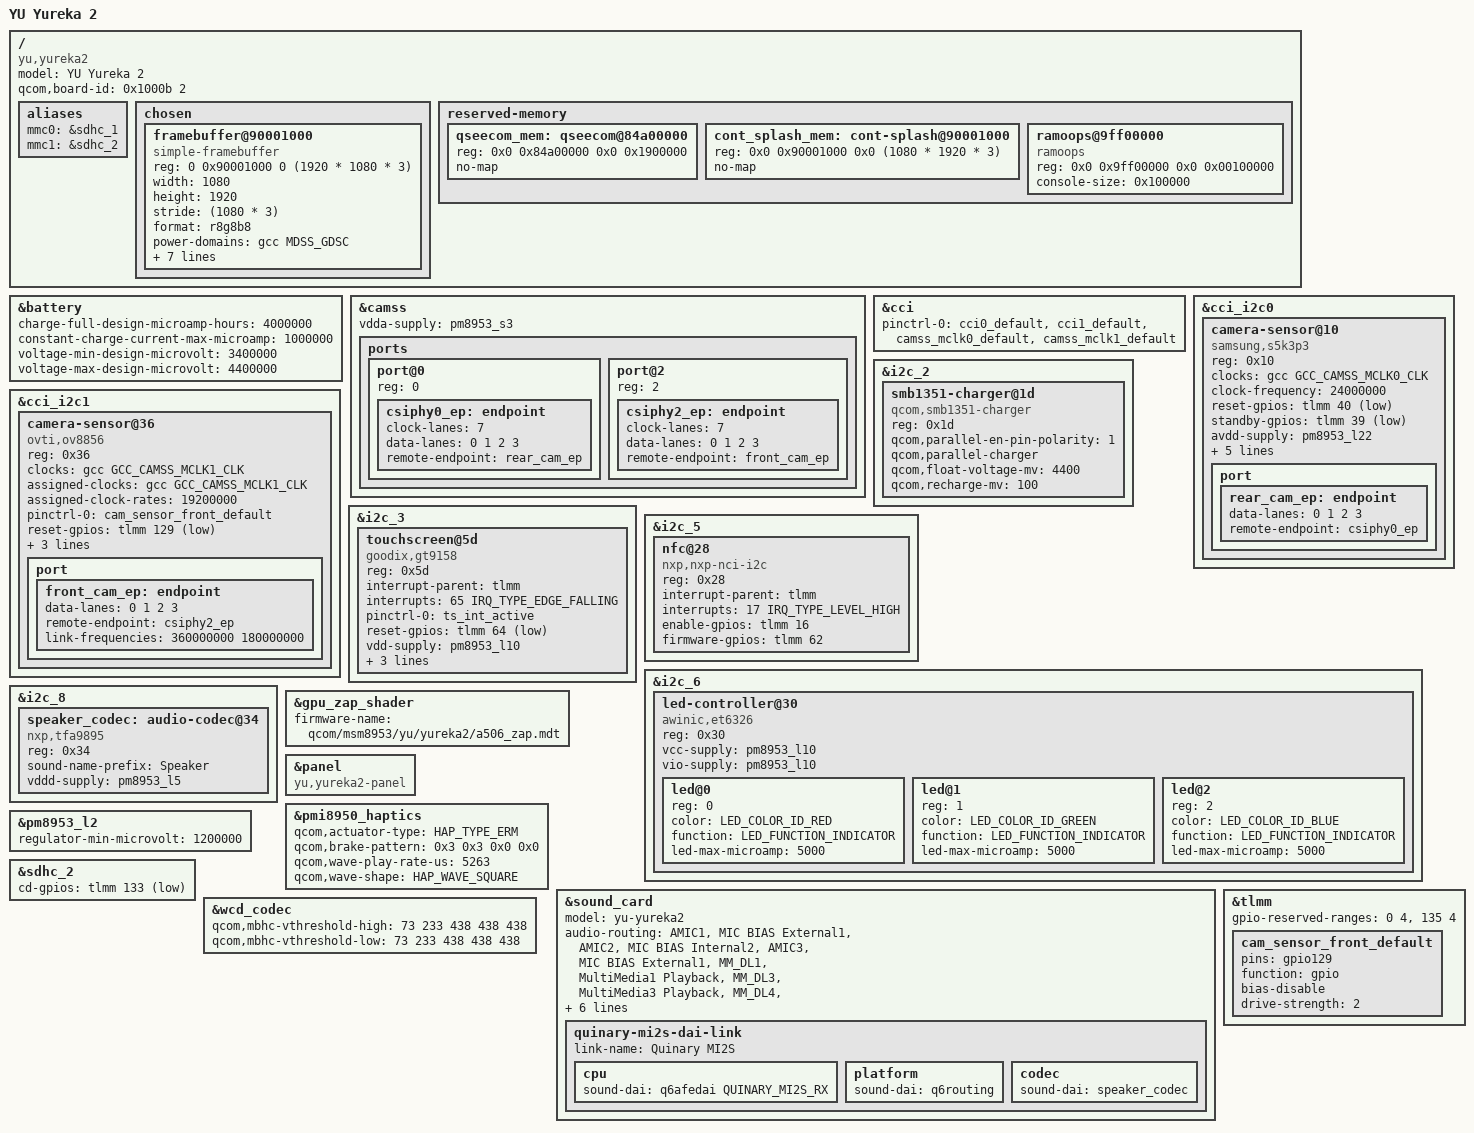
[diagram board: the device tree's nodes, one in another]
// SPDX-License-Identifier: BSD-3-Clause
/dts-v1/;

#include "msm8953-yu-common.dtsi"

/delete-node/ &cont_splash_mem;
/delete-node/ &qseecom_mem;

/ {
	model = "YU Yureka 2";
	compatible = "yu,yureka2", "qcom,msm8953";
	qcom,board-id = <0x1000b 2>;

	aliases {
		mmc0 = &sdhc_1;
		mmc1 = &sdhc_2;
	};

	chosen {
		#address-cells = <2>;
		#size-cells = <2>;
		ranges;

		framebuffer@90001000 {
			compatible = "simple-framebuffer";
			reg = <0 0x90001000 0 (1920 * 1080 * 3)>;

			width = <1080>;
			height = <1920>;
			stride = <(1080 * 3)>;
			format = "r8g8b8";

			power-domains = <&gcc MDSS_GDSC>;

			clocks = <&gcc GCC_MDSS_AHB_CLK>,
				 <&gcc GCC_MDSS_AXI_CLK>,
				 <&gcc GCC_MDSS_VSYNC_CLK>,
				 <&gcc GCC_MDSS_MDP_CLK>,
				 <&gcc GCC_MDSS_BYTE0_CLK>,
				 <&gcc GCC_MDSS_PCLK0_CLK>,
				 <&gcc GCC_MDSS_ESC0_CLK>;
		};
	};

	reserved-memory {
		qseecom_mem: qseecom@84a00000 {
			reg = <0x0 0x84a00000 0x0 0x1900000>;
			no-map;
		};

		cont_splash_mem: cont-splash@90001000 {
			reg = <0x0 0x90001000 0x0 (1080 * 1920 * 3)>;
			no-map;
		};

		ramoops@9ff00000 {
			compatible = "ramoops";
			reg = <0x0 0x9ff00000 0x0 0x00100000>;
			console-size = <0x100000>;
		};
	};
};

&battery {
	charge-full-design-microamp-hours = <4000000>;
	constant-charge-current-max-microamp = <1000000>;
	voltage-min-design-microvolt = <3400000>;
	voltage-max-design-microvolt = <4400000>;
};

&camss {
	status = "okay";
	vdda-supply = <&pm8953_s3>;

	ports {
		port@0 {
			reg = <0>;
			csiphy0_ep: endpoint {
				clock-lanes = <7>;
				data-lanes = <0 1 2 3>;
				remote-endpoint = <&rear_cam_ep>;
			};
		};

		port@2 {
			reg = <2>;
			csiphy2_ep: endpoint {
				clock-lanes = <7>;
				data-lanes = <0 1 2 3>;
				remote-endpoint = <&front_cam_ep>;
			};
		};
	};
};

&cci {
	pinctrl-names = "default";
	pinctrl-0 = <&cci0_default>,
		    <&cci1_default>,
		    <&camss_mclk0_default>,
		    <&camss_mclk1_default>;

	status = "okay";
};

&cci_i2c0 {
	camera-sensor@10 {
		compatible = "samsung,s5k3p3";
		reg = <0x10>;

		clocks = <&gcc GCC_CAMSS_MCLK0_CLK>;
		clock-frequency = <24000000>;

		reset-gpios = <&tlmm 40 GPIO_ACTIVE_LOW>;
		standby-gpios = <&tlmm 39 GPIO_ACTIVE_LOW>;

		avdd-supply = <&pm8953_l22>;
		dvdd-supply = <&pm8953_l2>;
		vio-supply = <&pm8953_l6>;
		aux-supply = <&pm8953_l17>;

		rotation = <270>;
		orientation = <1>;

		status = "okay";

		port {
			rear_cam_ep: endpoint {
				data-lanes = <0 1 2 3>;
				remote-endpoint = <&csiphy0_ep>;
			};
		};
	};
};

&cci_i2c1 {
	camera-sensor@36 {
		compatible = "ovti,ov8856";
		reg = <0x36>;

		clocks = <&gcc GCC_CAMSS_MCLK1_CLK>;
		clock-names = "xvclk";
		assigned-clocks = <&gcc GCC_CAMSS_MCLK1_CLK>;
		assigned-clock-rates = <19200000>;

		pinctrl-names = "default";
		pinctrl-0 = <&cam_sensor_front_default>;

		reset-gpios = <&tlmm 129 GPIO_ACTIVE_LOW>;

		avdd-supply = <&pm8953_l22>;
		dvdd-supply = <&pm8953_l23>;
		dovdd-supply = <&pm8953_l6>;

		status = "okay";

		port {
			front_cam_ep: endpoint {
				data-lanes = <0 1 2 3>;
				remote-endpoint = <&csiphy2_ep>;
				link-frequencies = /bits/ 64 <360000000 180000000>;
			};
		};
	};
};

&i2c_2 {
	status = "okay";

	smb1351-charger@1d {
		compatible = "qcom,smb1351-charger";
		reg = <0x1d>;
		qcom,parallel-en-pin-polarity = <1>;
		qcom,parallel-charger;
		qcom,float-voltage-mv = <4400>;
		qcom,recharge-mv = <100>;
	};
};

&i2c_3 {
	status = "okay";

	touchscreen@5d {
		compatible = "goodix,gt9158";
		reg = <0x5d>;

		interrupt-parent = <&tlmm>;
		interrupts = <65 IRQ_TYPE_EDGE_FALLING>;

		pinctrl-names = "default";
		pinctrl-0 = <&ts_int_active>;

		reset-gpios = <&tlmm 64 GPIO_ACTIVE_LOW>;

		vdd-supply = <&pm8953_l10>;
		vcc-i2c-supply = <&pm8953_l5>;

		touchscreen-size-x = <1080>;
		touchscreen-size-y = <1920>;
	};
};

&i2c_5 {
	status = "okay";

	nfc@28 {
		compatible = "nxp,nxp-nci-i2c";
		reg = <0x28>;

		interrupt-parent = <&tlmm>;
		interrupts = <17 IRQ_TYPE_LEVEL_HIGH>;

		enable-gpios = <&tlmm 16 GPIO_ACTIVE_HIGH>;
		firmware-gpios = <&tlmm 62 GPIO_ACTIVE_HIGH>;
	};
};

&i2c_6 {
	status = "okay";

	led-controller@30 {
		compatible = "awinic,et6326";
		reg = <0x30>;

		vcc-supply = <&pm8953_l10>;
		vio-supply = <&pm8953_l10>;

		#address-cells = <1>;
		#size-cells = <0>;

		led@0 {
			reg = <0>;
			color = <LED_COLOR_ID_RED>;
			function = LED_FUNCTION_INDICATOR;
			led-max-microamp = <5000>;
		};

		led@1 {
			reg = <1>;
			color = <LED_COLOR_ID_GREEN>;
			function = LED_FUNCTION_INDICATOR;
			led-max-microamp = <5000>;
		};

		led@2 {
			reg = <2>;
			color = <LED_COLOR_ID_BLUE>;
			function = LED_FUNCTION_INDICATOR;
			led-max-microamp = <5000>;
		};
	};
};

&i2c_8 {
	status = "okay";

	speaker_codec: audio-codec@34 {
		compatible = "nxp,tfa9895";
		reg = <0x34>;
		sound-name-prefix = "Speaker";
		vddd-supply = <&pm8953_l5>;
		#sound-dai-cells = <0>;
	};
};

&gpu_zap_shader {
	firmware-name = "qcom/msm8953/yu/yureka2/a506_zap.mdt";
};

&panel {
	compatible = "yu,yureka2-panel";
};

&pmi8950_haptics {
	qcom,actuator-type = <HAP_TYPE_ERM>;
	qcom,brake-pattern = <0x3 0x3 0x0 0x0>;
	qcom,wave-play-rate-us = <5263>;
	qcom,wave-shape = <HAP_WAVE_SQUARE>;

	status = "okay";
};

&pm8953_l2 {
	regulator-min-microvolt = <1200000>;
};

&sdhc_2 {
	cd-gpios = <&tlmm 133 GPIO_ACTIVE_LOW>;
};

&sound_card {
	model = "yu-yureka2";

	audio-routing =
		"AMIC1", "MIC BIAS External1",
		"AMIC2", "MIC BIAS Internal2",
		"AMIC3", "MIC BIAS External1",
		"MM_DL1", "MultiMedia1 Playback",
		"MM_DL3", "MultiMedia3 Playback",
		"MM_DL4", "MultiMedia4 Playback",
		"MultiMedia2 Capture", "MM_UL2";

	pinctrl-names = "default", "sleep";
	pinctrl-0 = <&cdc_pdm_lines_act &cdc_pdm_lines_2_act &cdc_pdm_comp_lines_act>;
	pinctrl-1 = <&cdc_pdm_lines_sus &cdc_pdm_lines_2_sus &cdc_pdm_comp_lines_sus>;

	status = "okay";

	quinary-mi2s-dai-link {
		link-name = "Quinary MI2S";

		cpu {
			sound-dai = <&q6afedai QUINARY_MI2S_RX>;
		};

		platform {
			sound-dai = <&q6routing>;
		};

		codec {
			sound-dai = <&speaker_codec>;
		};
	};
};

&wcd_codec {
	/delete-property/ qcom,gnd-jack-type-normally-open;
	/delete-property/ qcom,hphl-jack-type-normally-open;
	qcom,mbhc-vthreshold-high = <73 233 438 438 438>;
	qcom,mbhc-vthreshold-low = <73 233 438 438 438>;
};

&tlmm {
	gpio-reserved-ranges = <0 4>, <135 4>;

	cam_sensor_front_default: cam_sensor_front_default {
		pins = "gpio129";
		function = "gpio";
		bias-disable;
		drive-strength = <2>;
	};
};
